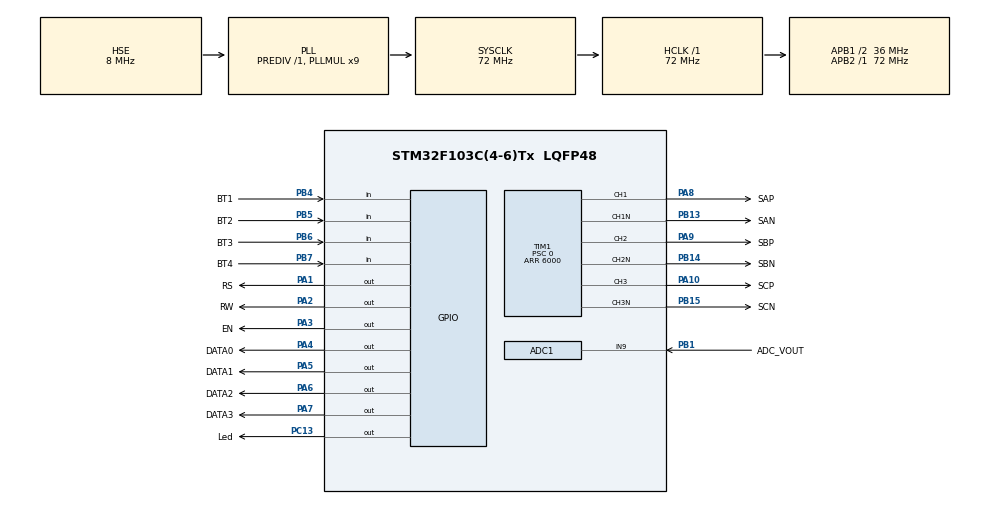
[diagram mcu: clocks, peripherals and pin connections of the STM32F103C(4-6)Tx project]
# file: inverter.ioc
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ADC1.Channel-6\#ChannelRegularConversion=ADC_CHANNEL_9
ADC1.ContinuousConvMode=ENABLE
ADC1.EnableInjectedConversion=DISABLE
ADC1.NbrOfConversionFlag=1
ADC1.Rank-6\#ChannelRegularConversion=1
ADC1.SamplingTime-6\#ChannelRegularConversion=ADC_SAMPLETIME_1CYCLE_5
ADC1.master=1
Mcu.Family=STM32F1
Mcu.Name=STM32F103C(4-6)Tx
Mcu.Package=LQFP48
NVIC.PriorityGroup=NVIC_PRIORITYGROUP_4
NVIC.TIM1_UP_IRQn=true\:0\:0\:false\:false\:true\:true\:true
PA1.GPIO_Label=RS
PA1.Signal=GPIO_Output
PA10.GPIO_Label=SCP
PA10.GPIO_Speed=GPIO_SPEED_FREQ_HIGH
PA10.Signal=S_TIM1_CH3
PA13.Mode=Serial_Wire
PA13.Signal=SYS_JTMS-SWDIO
PA14.Mode=Serial_Wire
PA14.Signal=SYS_JTCK-SWCLK
PA2.GPIO_Label=RW
PA2.Signal=GPIO_Output
PA3.GPIO_Label=EN
PA3.Signal=GPIO_Output
PA4.GPIO_Label=DATA0
PA4.Signal=GPIO_Output
PA5.GPIO_Label=DATA1
PA5.Signal=GPIO_Output
PA6.GPIO_Label=DATA2
PA6.Signal=GPIO_Output
PA7.GPIO_Label=DATA3
PA7.Signal=GPIO_Output
PA8.GPIO_Label=SAP
PA8.Signal=S_TIM1_CH1
PA9.GPIO_Label=SBP
PA9.GPIO_Speed=GPIO_SPEED_FREQ_HIGH
PA9.Signal=S_TIM1_CH2
PB1.GPIO_Label=ADC_VOUT
PB1.Signal=ADCx_IN9
PB13.GPIO_Label=SAN
PB13.Mode=PWM Generation1 CH1 CH1N
PB13.Signal=TIM1_CH1N
PB14.GPIO_Label=SBN
PB14.GPIO_Speed=GPIO_SPEED_FREQ_HIGH
PB14.Mode=PWM Generation2 CH2 CH2N
PB14.Signal=TIM1_CH2N
PB15.GPIO_Label=SCN
PB15.GPIO_Speed=GPIO_SPEED_FREQ_HIGH
PB15.Mode=PWM Generation3 CH3 CH3N
PB15.Signal=TIM1_CH3N
PB4.GPIO_Label=BT1
PB4.GPIO_PuPd=GPIO_PULLUP
PB4.Signal=GPIO_Input
PB5.GPIO_Label=BT2
PB5.GPIO_PuPd=GPIO_PULLUP
PB5.Signal=GPIO_Input
PB6.GPIO_Label=BT3
PB6.GPIO_PuPd=GPIO_PULLUP
PB6.Signal=GPIO_Input
PB7.GPIO_Label=BT4
PB7.GPIO_PuPd=GPIO_PULLUP
PB7.Signal=GPIO_Input
PC13-TAMPER-RTC.GPIO_Label=Led
PC13-TAMPER-RTC.GPIO_PuPd=GPIO_NOPULL
PC13-TAMPER-RTC.GPIO_Speed=GPIO_SPEED_FREQ_LOW
PC13-TAMPER-RTC.Signal=GPIO_Output
PC14-OSC32_IN.Mode=LSE-External-Oscillator
PC14-OSC32_IN.Signal=RCC_OSC32_IN
PC15-OSC32_OUT.Mode=LSE-External-Oscillator
PC15-OSC32_OUT.Signal=RCC_OSC32_OUT
PD0-OSC_IN.Mode=HSE-External-Oscillator
PD0-OSC_IN.Signal=RCC_OSC_IN
PD1-OSC_OUT.Mode=HSE-External-Oscillator
PD1-OSC_OUT.Signal=RCC_OSC_OUT
ProjectManager.HeapSize=0x200
ProjectManager.StackSize=0x400
ProjectManager.TargetToolchain=STM32CubeIDE
RCC.ADCPresc=RCC_ADCPCLK2_DIV8
RCC.AHBFreq_Value=72000000
RCC.APB1CLKDivider=RCC_HCLK_DIV2
RCC.APB1Freq_Value=36000000
RCC.APB1TimFreq_Value=72000000
RCC.APB2Freq_Value=72000000
RCC.APB2TimFreq_Value=72000000
RCC.HCLKFreq_Value=72000000
RCC.PLLMUL=RCC_PLL_MUL9
RCC.PLLSourceVirtual=RCC_PLLSOURCE_HSE
RCC.SYSCLKFreq_VALUE=72000000
RCC.SYSCLKSource=RCC_SYSCLKSOURCE_PLLCLK
RCC.USBFreq_Value=48000000
RCC.USBPrescaler=RCC_USBCLKSOURCE_PLL_DIV1_5
SH.ADCx_IN9.0=ADC1_IN9,IN9
SH.S_TIM1_CH1.0=TIM1_CH1,PWM Generation1 CH1 CH1N
SH.S_TIM1_CH2.0=TIM1_CH2,PWM Generation2 CH2 CH2N
SH.S_TIM1_CH3.0=TIM1_CH3,PWM Generation3 CH3 CH3N
TIM1.Channel-PWM\ Generation1\ CH1\ CH1N=TIM_CHANNEL_1
TIM1.Channel-PWM\ Generation2\ CH2\ CH2N=TIM_CHANNEL_2
TIM1.Channel-PWM\ Generation3\ CH3\ CH3N=TIM_CHANNEL_3
TIM1.CounterMode=TIM_COUNTERMODE_UP
TIM1.DeadTime=144
TIM1.OCNPolarity_1=TIM_OCNPOLARITY_LOW
TIM1.OCNPolarity_2=TIM_OCNPOLARITY_LOW
TIM1.OCNPolarity_3=TIM_OCNPOLARITY_LOW
TIM1.Period=6000
TIM1.Prescaler=0
VP_TIM1_VS_ClockSourceINT.Mode=Internal
board=custom

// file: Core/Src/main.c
/* USER CODE BEGIN Header */
/**
  ******************************************************************************
  * @file           : main.c
  * @brief          : Main program body
  ******************************************************************************
  * @attention
  *
  * <h2><center>&copy; Copyright (c) 2023 STMicroelectronics.
  * All rights reserved.</center></h2>
  *
  * This software component is licensed by ST under BSD 3-Clause license,
  * the "License"; You may not use this file except in compliance with the
  * License. You may obtain a copy of the License at:
  *                        opensource.org/licenses/BSD-3-Clause
  *
  ******************************************************************************
  */
/* USER CODE END Header */
#include "main.h"

/* USER CODE BEGIN Includes */

#include "app.h"

/* USER CODE END Includes */

/* USER CODE BEGIN PTD */

app_t app;

/* USER CODE END PTD */

ADC_HandleTypeDef hadc1;

TIM_HandleTypeDef htim1;

void SystemClock_Config(void);
static void MX_GPIO_Init(void);
static void MX_ADC1_Init(void);
static void MX_TIM1_Init(void);

int main(void)
{

  /* MCU Configuration--------------------------------------------------------*/

  /* Reset of all peripherals, Initializes the Flash interface and the Systick. */
  HAL_Init();

  /* Configure the system clock */
  SystemClock_Config();

  /* Initialize all configured peripherals */
  MX_GPIO_Init();
  MX_ADC1_Init();
  MX_TIM1_Init();
  /* USER CODE BEGIN 2 */

  HAL_ADC_Start(&hadc1);

  lcd16x2_init_4bits(RS_GPIO_Port, RS_Pin, EN_Pin,
		  DATA0_GPIO_Port, DATA0_Pin, DATA1_Pin, DATA2_Pin, DATA3_Pin);

  app_init(&app);

  HAL_TIM_Base_Start_IT(&htim1);

  /* USER CODE END 2 */

  /* Infinite loop */
  while (1)
  {

    /* USER CODE BEGIN 3 */
	app_loop(&app);
  }
  /* USER CODE END 3 */
}

void SystemClock_Config(void)
{
  RCC_OscInitTypeDef RCC_OscInitStruct = {0};
  RCC_ClkInitTypeDef RCC_ClkInitStruct = {0};
  RCC_PeriphCLKInitTypeDef PeriphClkInit = {0};

  /** Initializes the RCC Oscillators according to the specified parameters
  * in the RCC_OscInitTypeDef structure.
  */
  RCC_OscInitStruct.OscillatorType = RCC_OSCILLATORTYPE_HSE;
  RCC_OscInitStruct.HSEState = RCC_HSE_ON;
  RCC_OscInitStruct.HSEPredivValue = RCC_HSE_PREDIV_DIV1;
  RCC_OscInitStruct.HSIState = RCC_HSI_ON;
  RCC_OscInitStruct.PLL.PLLState = RCC_PLL_ON;
  RCC_OscInitStruct.PLL.PLLSource = RCC_PLLSOURCE_HSE;
  RCC_OscInitStruct.PLL.PLLMUL = RCC_PLL_MUL9;
  if (HAL_RCC_OscConfig(&RCC_OscInitStruct) != HAL_OK)
  {
    Error_Handler();
  }
  /** Initializes the CPU, AHB and APB buses clocks
  */
  RCC_ClkInitStruct.ClockType = RCC_CLOCKTYPE_HCLK|RCC_CLOCKTYPE_SYSCLK
                              |RCC_CLOCKTYPE_PCLK1|RCC_CLOCKTYPE_PCLK2;
  RCC_ClkInitStruct.SYSCLKSource = RCC_SYSCLKSOURCE_PLLCLK;
  RCC_ClkInitStruct.AHBCLKDivider = RCC_SYSCLK_DIV1;
  RCC_ClkInitStruct.APB1CLKDivider = RCC_HCLK_DIV2;
  RCC_ClkInitStruct.APB2CLKDivider = RCC_HCLK_DIV1;

  if (HAL_RCC_ClockConfig(&RCC_ClkInitStruct, FLASH_LATENCY_2) != HAL_OK)
  {
    Error_Handler();
  }
  PeriphClkInit.PeriphClockSelection = RCC_PERIPHCLK_ADC;
  PeriphClkInit.AdcClockSelection = RCC_ADCPCLK2_DIV8;
  if (HAL_RCCEx_PeriphCLKConfig(&PeriphClkInit) != HAL_OK)
  {
    Error_Handler();
  }
}

static void MX_ADC1_Init(void)
{

  ADC_ChannelConfTypeDef sConfig = {0};

  /** Common config
  */
  hadc1.Instance = ADC1;
  hadc1.Init.ScanConvMode = ADC_SCAN_DISABLE;
  hadc1.Init.ContinuousConvMode = ENABLE;
  hadc1.Init.DiscontinuousConvMode = DISABLE;
  hadc1.Init.ExternalTrigConv = ADC_SOFTWARE_START;
  hadc1.Init.DataAlign = ADC_DATAALIGN_RIGHT;
  hadc1.Init.NbrOfConversion = 1;
  if (HAL_ADC_Init(&hadc1) != HAL_OK)
  {
    Error_Handler();
  }
  /** Configure Regular Channel
  */
  sConfig.Channel = ADC_CHANNEL_9;
  sConfig.Rank = ADC_REGULAR_RANK_1;
  sConfig.SamplingTime = ADC_SAMPLETIME_1CYCLE_5;
  if (HAL_ADC_ConfigChannel(&hadc1, &sConfig) != HAL_OK)
  {
    Error_Handler();
  }

}

static void MX_TIM1_Init(void)
{

  TIM_ClockConfigTypeDef sClockSourceConfig = {0};
  TIM_MasterConfigTypeDef sMasterConfig = {0};
  TIM_OC_InitTypeDef sConfigOC = {0};
  TIM_BreakDeadTimeConfigTypeDef sBreakDeadTimeConfig = {0};

  htim1.Instance = TIM1;
  htim1.Init.Prescaler = 0;
  htim1.Init.CounterMode = TIM_COUNTERMODE_UP;
  htim1.Init.Period = 6000;
  htim1.Init.ClockDivision = TIM_CLOCKDIVISION_DIV1;
  htim1.Init.RepetitionCounter = 0;
  htim1.Init.AutoReloadPreload = TIM_AUTORELOAD_PRELOAD_DISABLE;
  if (HAL_TIM_Base_Init(&htim1) != HAL_OK)
  {
    Error_Handler();
  }
  sClockSourceConfig.ClockSource = TIM_CLOCKSOURCE_INTERNAL;
  if (HAL_TIM_ConfigClockSource(&htim1, &sClockSourceConfig) != HAL_OK)
  {
    Error_Handler();
  }
  if (HAL_TIM_PWM_Init(&htim1) != HAL_OK)
  {
    Error_Handler();
  }
  sMasterConfig.MasterOutputTrigger = TIM_TRGO_RESET;
  sMasterConfig.MasterSlaveMode = TIM_MASTERSLAVEMODE_DISABLE;
  if (HAL_TIMEx_MasterConfigSynchronization(&htim1, &sMasterConfig) != HAL_OK)
  {
    Error_Handler();
  }
  sConfigOC.OCMode = TIM_OCMODE_PWM1;
  sConfigOC.Pulse = 0;
  sConfigOC.OCPolarity = TIM_OCPOLARITY_HIGH;
  sConfigOC.OCNPolarity = TIM_OCNPOLARITY_LOW;
  sConfigOC.OCFastMode = TIM_OCFAST_DISABLE;
  sConfigOC.OCIdleState = TIM_OCIDLESTATE_RESET;
  sConfigOC.OCNIdleState = TIM_OCNIDLESTATE_RESET;
  if (HAL_TIM_PWM_ConfigChannel(&htim1, &sConfigOC, TIM_CHANNEL_1) != HAL_OK)
  {
    Error_Handler();
  }
  if (HAL_TIM_PWM_ConfigChannel(&htim1, &sConfigOC, TIM_CHANNEL_2) != HAL_OK)
  {
    Error_Handler();
  }
  if (HAL_TIM_PWM_ConfigChannel(&htim1, &sConfigOC, TIM_CHANNEL_3) != HAL_OK)
  {
    Error_Handler();
  }
  sBreakDeadTimeConfig.OffStateRunMode = TIM_OSSR_DISABLE;
  sBreakDeadTimeConfig.OffStateIDLEMode = TIM_OSSI_DISABLE;
  sBreakDeadTimeConfig.LockLevel = TIM_LOCKLEVEL_OFF;
  sBreakDeadTimeConfig.DeadTime = 144;
  sBreakDeadTimeConfig.BreakState = TIM_BREAK_DISABLE;
  sBreakDeadTimeConfig.BreakPolarity = TIM_BREAKPOLARITY_HIGH;
  sBreakDeadTimeConfig.AutomaticOutput = TIM_AUTOMATICOUTPUT_DISABLE;
  if (HAL_TIMEx_ConfigBreakDeadTime(&htim1, &sBreakDeadTimeConfig) != HAL_OK)
  {
    Error_Handler();
  }
  HAL_TIM_MspPostInit(&htim1);

}

static void MX_GPIO_Init(void)
{
  GPIO_InitTypeDef GPIO_InitStruct = {0};

  /* GPIO Ports Clock Enable */
  __HAL_RCC_GPIOC_CLK_ENABLE();
  __HAL_RCC_GPIOD_CLK_ENABLE();
  __HAL_RCC_GPIOA_CLK_ENABLE();
  __HAL_RCC_GPIOB_CLK_ENABLE();

  /*Configure GPIO pin Output Level */
  HAL_GPIO_WritePin(Led_GPIO_Port, Led_Pin, GPIO_PIN_RESET);

  /*Configure GPIO pin Output Level */
  HAL_GPIO_WritePin(GPIOA, RS_Pin|RW_Pin|EN_Pin|DATA0_Pin
                          |DATA1_Pin|DATA2_Pin|DATA3_Pin, GPIO_PIN_RESET);

  /*Configure GPIO pin : Led_Pin */
  GPIO_InitStruct.Pin = Led_Pin;
  GPIO_InitStruct.Mode = GPIO_MODE_OUTPUT_PP;
  GPIO_InitStruct.Pull = GPIO_NOPULL;
  GPIO_InitStruct.Speed = GPIO_SPEED_FREQ_LOW;
  HAL_GPIO_Init(Led_GPIO_Port, &GPIO_InitStruct);

  /*Configure GPIO pins : RS_Pin RW_Pin EN_Pin DATA0_Pin
                           DATA1_Pin DATA2_Pin DATA3_Pin */
  GPIO_InitStruct.Pin = RS_Pin|RW_Pin|EN_Pin|DATA0_Pin
                          |DATA1_Pin|DATA2_Pin|DATA3_Pin;
  GPIO_InitStruct.Mode = GPIO_MODE_OUTPUT_PP;
  GPIO_InitStruct.Pull = GPIO_NOPULL;
  GPIO_InitStruct.Speed = GPIO_SPEED_FREQ_LOW;
  HAL_GPIO_Init(GPIOA, &GPIO_InitStruct);

  /*Configure GPIO pins : BT1_Pin BT2_Pin BT3_Pin BT4_Pin */
  GPIO_InitStruct.Pin = BT1_Pin|BT2_Pin|BT3_Pin|BT4_Pin;
  GPIO_InitStruct.Mode = GPIO_MODE_INPUT;
  GPIO_InitStruct.Pull = GPIO_PULLUP;
  HAL_GPIO_Init(GPIOB, &GPIO_InitStruct);

}

/* USER CODE BEGIN 4 */

//Callback timer
void HAL_TIM_PeriodElapsedCallback(TIM_HandleTypeDef *htim){
	app_isr(&app);
}
/* USER CODE END 4 */

void Error_Handler(void)
{
  __disable_irq();
  while (1)
  {
  }
}

/************************ (C) COPYRIGHT STMicroelectronics *****END OF FILE****/
